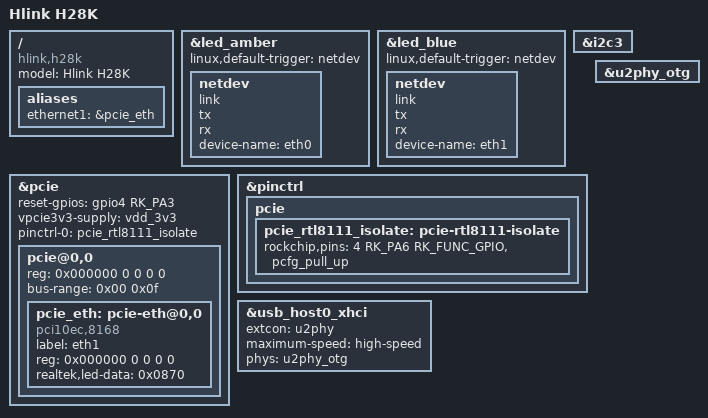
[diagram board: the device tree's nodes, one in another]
// SPDX-License-Identifier: (GPL-2.0+ OR MIT)
/*
 * Copyright (c) 2022 Rockchip Electronics Co., Ltd.
 * Copyright (c) 2025 flippy <flippy@sina.com>
 */

#include "rk3528-hlink.dtsi"

/ {
	model = "Hlink H28K";
	compatible = "hlink,h28k", "rockchip,rk3528";

	aliases {
		ethernet1 = &pcie_eth;
	};
};

&led_amber {
	linux,default-trigger = "netdev";

	netdev {
		link;
		tx;
		rx;
		device-name = "eth0";
	};
};

&led_blue {
	linux,default-trigger = "netdev";

	netdev {
		link;
		tx;
		rx;
		device-name = "eth1";
	};
};

&i2c3 {
	status = "okay";
};

&pcie {
	status = "okay";
	reset-gpios = <&gpio4 RK_PA3 GPIO_ACTIVE_HIGH>;
	vpcie3v3-supply = <&vdd_3v3>;

	pinctrl-names = "default";
	pinctrl-0 = <&pcie_rtl8111_isolate>;

	pcie@0,0 {
		reg = <0x000000 0 0 0 0>;
		#address-cells = <3>;
		#size-cells = <2>;

		bus-range = <0x00 0x0f>;
		device_type = "pci";
		ranges;

		pcie_eth: pcie-eth@0,0 {
			compatible = "pci10ec,8168";
			label = "eth1";
			reg = <0x000000 0 0 0 0>;
			realtek,led-data = <0x0870>;
		};
	};
};

&pinctrl {
	pcie {
		pcie_rtl8111_isolate: pcie-rtl8111-isolate {
			rockchip,pins = <4 RK_PA6 RK_FUNC_GPIO &pcfg_pull_up>;
		};
	};
};

&u2phy_otg {
	status = "okay";
};

/* otg mode only */
&usb_host0_xhci {
	extcon = <&u2phy>;
	maximum-speed = "high-speed";
	phys = <&u2phy_otg>;
	phy-names = "usb2-phy";
	status = "okay";
};
